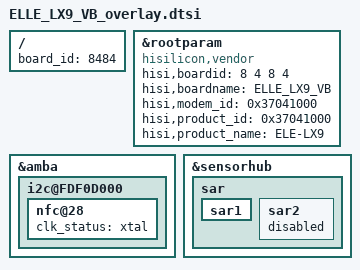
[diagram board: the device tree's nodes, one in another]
/**
 * Copyright (C) 2014 Hisilicon Ltd.
 *
 *  This program is free software; you can redistribute it and/or modify
 *  it under the terms of the GNU General Public License version 2 as
 *  publishhed by the Free Software Foundation.
 */

/include/ "ELLE_TUGL_VB_DIFEMOLD_overlay.dtsi"

/ {
    board_id = <8484>;
};
    &rootparam{
		compatible = "hisilicon,vendor";
		hisi,boardid = <8 4 8 4>;
		hisi,boardname = "ELLE_LX9_VB";
		hisi,modem_id = <0x37041000>;
		hisi,product_id = <0x37041000>;
		hisi,product_name = "ELE-LX9";
	};
     &amba {
         i2c@FDF0D000 {
                 nfc@28{
                         clk_status = "xtal";
                 };
         };
     };

     &sensorhub{
                 sar{
                         sar1{
                                status = "ok";
                         };
                         sar2{
                                 status = "disabled";
                         };
                 };
     };
